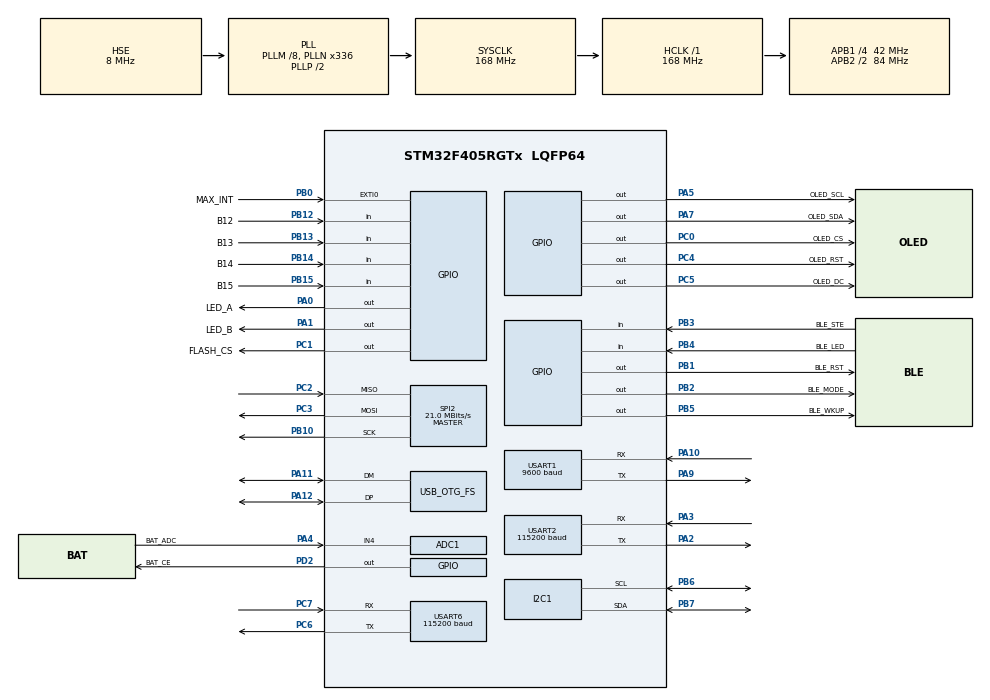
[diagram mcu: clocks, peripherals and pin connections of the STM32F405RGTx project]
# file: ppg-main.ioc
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ADC1.Channel-0\#ChannelRegularConversion=ADC_CHANNEL_4
ADC1.NbrOfConversionFlag=1
ADC1.Rank-0\#ChannelRegularConversion=1
ADC1.SamplingTime-0\#ChannelRegularConversion=ADC_SAMPLETIME_3CYCLES
ADC1.master=1
FATFS._MAX_SS=512
FATFS._MIN_SS=512
Mcu.Family=STM32F4
Mcu.Name=STM32F405RGTx
Mcu.Package=LQFP64
NVIC.OTG_FS_IRQn=true\:0\:0\:false\:false\:true\:false
NVIC.PriorityGroup=NVIC_PRIORITYGROUP_4
NVIC.TIM8_TRG_COM_TIM14_IRQn=true\:0\:0\:false\:false\:true\:false
NVIC.TimeBase=TIM8_TRG_COM_TIM14_IRQn
NVIC.TimeBaseIP=TIM14
PA0-WKUP.GPIO_Label=LED_A
PA0-WKUP.GPIO_Speed=GPIO_SPEED_FREQ_VERY_HIGH
PA0-WKUP.Signal=GPIO_Output
PA1.GPIO_Label=LED_B
PA1.GPIO_Speed=GPIO_SPEED_FREQ_VERY_HIGH
PA1.Signal=GPIO_Output
PA10.Mode=Asynchronous
PA10.Signal=USART1_RX
PA11.Mode=Device_Only
PA11.Signal=USB_OTG_FS_DM
PA12.Mode=Device_Only
PA12.Signal=USB_OTG_FS_DP
PA13.Mode=Serial_Wire
PA13.Signal=SYS_JTMS-SWDIO
PA14.Mode=Serial_Wire
PA14.Signal=SYS_JTCK-SWCLK
PA2.Mode=Asynchronous
PA2.Signal=USART2_TX
PA3.Mode=Asynchronous
PA3.Signal=USART2_RX
PA4.GPIO_Label=BAT_ADC
PA4.Signal=SharedAnalog_PA4
PA5.GPIO_Label=OLED_SCL
PA5.GPIO_Speed=GPIO_SPEED_FREQ_VERY_HIGH
PA5.Signal=GPIO_Output
PA7.GPIO_Label=OLED_SDA
PA7.GPIO_Speed=GPIO_SPEED_FREQ_VERY_HIGH
PA7.Signal=GPIO_Output
PA9.Mode=Asynchronous
PA9.Signal=USART1_TX
PB0.GPIO_Label=MAX_INT
PB0.Signal=GPXTI0
PB1.GPIO_Label=BLE_RST
PB1.GPIO_ModeDefaultOutputPP=GPIO_MODE_OUTPUT_OD
PB1.GPIO_PuPd=GPIO_NOPULL
PB1.GPIO_Speed=GPIO_SPEED_FREQ_VERY_HIGH
PB1.PinState=GPIO_PIN_SET
PB1.Signal=GPIO_Output
PB10.Mode=Full_Duplex_Master
PB10.Signal=SPI2_SCK
PB12.GPIO_Label=B12
PB12.GPIO_Mode=GPIO_MODE_INPUT
PB12.GPIO_PuPd=GPIO_PULLUP
PB12.Signal=GPIO_Input
PB13.GPIO_Label=B13
PB13.GPIO_Mode=GPIO_MODE_INPUT
PB13.GPIO_PuPd=GPIO_PULLUP
PB13.Signal=GPIO_Input
PB14.GPIO_Label=B14
PB14.GPIO_Mode=GPIO_MODE_INPUT
PB14.GPIO_PuPd=GPIO_PULLUP
PB14.Signal=GPIO_Input
PB15.GPIO_Label=B15
PB15.GPIO_Mode=GPIO_MODE_INPUT
PB15.GPIO_PuPd=GPIO_PULLUP
PB15.Signal=GPIO_Input
PB2.GPIO_Label=BLE_MODE
PB2.GPIO_ModeDefaultOutputPP=GPIO_MODE_OUTPUT_OD
PB2.GPIO_PuPd=GPIO_NOPULL
PB2.GPIO_Speed=GPIO_SPEED_FREQ_VERY_HIGH
PB2.PinState=GPIO_PIN_SET
PB2.Signal=GPIO_Output
PB3.GPIO_Label=BLE_STE
PB3.Signal=GPIO_Input
PB4.GPIO_Label=BLE_LED
PB4.Signal=GPIO_Input
PB5.GPIO_Label=BLE_WKUP
PB5.GPIO_ModeDefaultOutputPP=GPIO_MODE_OUTPUT_OD
PB5.GPIO_PuPd=GPIO_NOPULL
PB5.GPIO_Speed=GPIO_SPEED_FREQ_VERY_HIGH
PB5.PinState=GPIO_PIN_SET
PB5.Signal=GPIO_Output
PB6.Mode=I2C
PB6.Signal=I2C1_SCL
PB7.Mode=I2C
PB7.Signal=I2C1_SDA
PC0.GPIO_Label=OLED_CS
PC0.GPIO_Speed=GPIO_SPEED_FREQ_VERY_HIGH
PC0.PinState=GPIO_PIN_SET
PC0.Signal=GPIO_Output
PC1.GPIO_Label=FLASH_CS
PC1.GPIO_Speed=GPIO_SPEED_FREQ_VERY_HIGH
PC1.PinState=GPIO_PIN_SET
PC1.Signal=GPIO_Output
PC14-OSC32_IN.Mode=LSE-External-Oscillator
PC14-OSC32_IN.Signal=RCC_OSC32_IN
PC15-OSC32_OUT.Mode=LSE-External-Oscillator
PC15-OSC32_OUT.Signal=RCC_OSC32_OUT
PC2.Mode=Full_Duplex_Master
PC2.Signal=SPI2_MISO
PC3.Mode=Full_Duplex_Master
PC3.Signal=SPI2_MOSI
PC4.GPIO_Label=OLED_RST
PC4.GPIO_Speed=GPIO_SPEED_FREQ_VERY_HIGH
PC4.Signal=GPIO_Output
PC5.GPIO_Label=OLED_DC
PC5.GPIO_Speed=GPIO_SPEED_FREQ_VERY_HIGH
PC5.Signal=GPIO_Output
PC6.Mode=Asynchronous
PC6.Signal=USART6_TX
PC7.Mode=Asynchronous
PC7.Signal=USART6_RX
PD2.GPIO_Label=BAT_CE
PD2.GPIO_Speed=GPIO_SPEED_FREQ_VERY_HIGH
PD2.PinState=GPIO_PIN_SET
PD2.Signal=GPIO_Output
PH0-OSC_IN.Mode=HSE-External-Oscillator
PH0-OSC_IN.Signal=RCC_OSC_IN
PH1-OSC_OUT.Mode=HSE-External-Oscillator
PH1-OSC_OUT.Signal=RCC_OSC_OUT
ProjectManager.HeapSize=0x400
ProjectManager.StackSize=0x800
ProjectManager.TargetToolchain=SW4STM32
RCC.48MHZClocksFreq_Value=48000000
RCC.AHBFreq_Value=168000000
RCC.APB1CLKDivider=RCC_HCLK_DIV4
RCC.APB1Freq_Value=42000000
RCC.APB1TimFreq_Value=84000000
RCC.APB2CLKDivider=RCC_HCLK_DIV2
RCC.APB2Freq_Value=84000000
RCC.APB2TimFreq_Value=168000000
RCC.CortexFreq_Value=168000000
RCC.EnbaleCSS=true
RCC.HCLKFreq_Value=168000000
RCC.HSE_VALUE=8000000
RCC.HSICalibrationValue=8
RCC.HSI_VALUE=16000000
RCC.PLLM=8
RCC.PLLN=336
RCC.PLLQ=7
RCC.SYSCLKFreq_VALUE=168000000
RCC.SYSCLKSource=RCC_SYSCLKSOURCE_PLLCLK
RCC.VCOOutputFreq_Value=336000000
SH.SharedAnalog_PA4.0=GPIO_Analog
SH.SharedAnalog_PA4.1=ADC1_IN4,IN4
SPI2.BaudRatePrescaler=SPI_BAUDRATEPRESCALER_2
SPI2.CalculateBaudRate=21.0 MBits/s
SPI2.Direction=SPI_DIRECTION_2LINES
SPI2.Mode=SPI_MODE_MASTER
SPI2.VirtualType=VM_MASTER
USART1.BaudRate=9600
USART1.VirtualMode=VM_ASYNC
USART2.BaudRate=115200
USART2.VirtualMode=VM_ASYNC
USART6.BaudRate=115200
USART6.VirtualMode=VM_ASYNC
USB_DEVICE.CLASS_NAME_FS=MSC
USB_DEVICE.CONFIGURATION_STRING_MSC_FS=PPGColle Config
USB_DEVICE.INTERFACE_STRING_MSC_FS=PPGColle Interface
USB_DEVICE.MANUFACTURER_STRING-MSC_FS=NSDN
USB_DEVICE.PRODUCT_STRING_MSC_FS=PPGColle Storage
USB_DEVICE.VirtualMode-MSC_FS=Msc
USB_DEVICE.VirtualModeFS=Msc_FS
USB_OTG_FS.VirtualMode=Device_Only
VP_FATFS_VS_Generic.Mode=User_defined
VP_RNG_VS_RNG.Mode=RNG_Activate
VP_RTC_VS_RTC_Activate.Mode=RTC_Enabled
VP_SYS_VS_tim14.Mode=TIM14
VP_USB_DEVICE_VS_USB_DEVICE_MSC_FS.Mode=MSC_FS
board=ppg-main

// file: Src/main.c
/**
  ******************************************************************************
  * @file           : main.c
  * @brief          : Main program body
  ******************************************************************************
  * This notice applies to any and all portions of this file
  * that are not between comment pairs USER CODE BEGIN and
  * USER CODE END. Other portions of this file, whether
  * inserted by the user or by software development tools
  * are owned by their respective copyright owners.
  *
  * Copyright (c) 2018 STMicroelectronics International N.V.
  * All rights reserved.
  *
  * Redistribution and use in source and binary forms, with or without
  * modification, are permitted, provided that the following conditions are met:
  *
  * 1. Redistribution of source code must retain the above copyright notice,
  *    this list of conditions and the following disclaimer.
  * 2. Redistributions in binary form must reproduce the above copyright notice,
  *    this list of conditions and the following disclaimer in the documentation
  *    and/or other materials provided with the distribution.
  * 3. Neither the name of STMicroelectronics nor the names of other
  *    contributors to this software may be used to endorse or promote products
  *    derived from this software without specific written permission.
  * 4. This software, including modifications and/or derivative works of this
  *    software, must execute solely and exclusively on microcontroller or
  *    microprocessor devices manufactured by or for STMicroelectronics.
  * 5. Redistribution and use of this software other than as permitted under
  *    this license is void and will automatically terminate your rights under
  *    this license.
  *
  * THIS SOFTWARE IS PROVIDED BY STMICROELECTRONICS AND CONTRIBUTORS "AS IS"
  * AND ANY EXPRESS, IMPLIED OR STATUTORY WARRANTIES, INCLUDING, BUT NOT
  * LIMITED TO, THE IMPLIED WARRANTIES OF MERCHANTABILITY, FITNESS FOR A
  * PARTICULAR PURPOSE AND NON-INFRINGEMENT OF THIRD PARTY INTELLECTUAL PROPERTY
  * RIGHTS ARE DISCLAIMED TO THE FULLEST EXTENT PERMITTED BY LAW. IN NO EVENT
  * SHALL STMICROELECTRONICS OR CONTRIBUTORS BE LIABLE FOR ANY DIRECT, INDIRECT,
  * INCIDENTAL, SPECIAL, EXEMPLARY, OR CONSEQUENTIAL DAMAGES (INCLUDING, BUT NOT
  * LIMITED TO, PROCUREMENT OF SUBSTITUTE GOODS OR SERVICES; LOSS OF USE, DATA,
  * OR PROFITS; OR BUSINESS INTERRUPTION) HOWEVER CAUSED AND ON ANY THEORY OF
  * LIABILITY, WHETHER IN CONTRACT, STRICT LIABILITY, OR TORT (INCLUDING
  * NEGLIGENCE OR OTHERWISE) ARISING IN ANY WAY OUT OF THE USE OF THIS SOFTWARE,
  * EVEN IF ADVISED OF THE POSSIBILITY OF SUCH DAMAGE.
  *
  ******************************************************************************
  */
#include "main.h"
#include "stm32f4xx_hal.h"
#include "fatfs.h"
#include "usb_device.h"

/* USER CODE BEGIN Includes */
#include "ppg_bios.h"
#include "ppg_system.h"

/* USER CODE END Includes */

ADC_HandleTypeDef hadc1;

I2C_HandleTypeDef hi2c1;

RNG_HandleTypeDef hrng;

RTC_HandleTypeDef hrtc;

SPI_HandleTypeDef hspi2;

UART_HandleTypeDef huart1;
UART_HandleTypeDef huart2;
UART_HandleTypeDef huart6;

/* USER CODE BEGIN PV */
/* Private variables ---------------------------------------------------------*/
/* USER CODE END PV */

void SystemClock_Config(void);
static void MX_GPIO_Init(void);
static void MX_SPI2_Init(void);
static void MX_I2C1_Init(void);
static void MX_USART1_UART_Init(void);
static void MX_USART2_UART_Init(void);
static void MX_USART6_UART_Init(void);
static void MX_ADC1_Init(void);
static void MX_RNG_Init(void);
static void MX_RTC_Init(void);

/* USER CODE BEGIN PFP */
/* Private function prototypes -----------------------------------------------*/
/* USER CODE END PFP */

int main(void)
{

  /* MCU Configuration----------------------------------------------------------*/

  /* Reset of all peripherals, Initializes the Flash interface and the Systick. */
  HAL_Init();

  /* Configure the system clock */
  SystemClock_Config();

  /* Initialize all configured peripherals */
  MX_GPIO_Init();
  MX_SPI2_Init();
  MX_I2C1_Init();
  MX_USART1_UART_Init();
  MX_USART2_UART_Init();
  MX_USART6_UART_Init();
  MX_FATFS_Init();
  MX_USB_DEVICE_Init();
  MX_ADC1_Init();
  MX_RNG_Init();
  MX_RTC_Init();
  /* USER CODE BEGIN 2 */
  hardwareInit();

  /* USER CODE END 2 */

  /* Infinite loop */
  /* USER CODE BEGIN WHILE */
  while (1)
  {
	  systemWork();
  /* USER CODE END WHILE */

  }

}

void SystemClock_Config(void)
{

  RCC_OscInitTypeDef RCC_OscInitStruct;
  RCC_ClkInitTypeDef RCC_ClkInitStruct;
  RCC_PeriphCLKInitTypeDef PeriphClkInitStruct;

    /**Configure the main internal regulator output voltage
    */
  __HAL_RCC_PWR_CLK_ENABLE();

  __HAL_PWR_VOLTAGESCALING_CONFIG(PWR_REGULATOR_VOLTAGE_SCALE1);

    /**Initializes the CPU, AHB and APB busses clocks
    */
  RCC_OscInitStruct.OscillatorType = RCC_OSCILLATORTYPE_LSI|RCC_OSCILLATORTYPE_HSE;
  RCC_OscInitStruct.HSEState = RCC_HSE_ON;
  RCC_OscInitStruct.LSIState = RCC_LSI_ON;
  RCC_OscInitStruct.PLL.PLLState = RCC_PLL_ON;
  RCC_OscInitStruct.PLL.PLLSource = RCC_PLLSOURCE_HSE;
  RCC_OscInitStruct.PLL.PLLM = 8;
  RCC_OscInitStruct.PLL.PLLN = 336;
  RCC_OscInitStruct.PLL.PLLP = RCC_PLLP_DIV2;
  RCC_OscInitStruct.PLL.PLLQ = 7;
  if (HAL_RCC_OscConfig(&RCC_OscInitStruct) != HAL_OK)
  {
    _Error_Handler(__FILE__, __LINE__);
  }

    /**Initializes the CPU, AHB and APB busses clocks
    */
  RCC_ClkInitStruct.ClockType = RCC_CLOCKTYPE_HCLK|RCC_CLOCKTYPE_SYSCLK
                              |RCC_CLOCKTYPE_PCLK1|RCC_CLOCKTYPE_PCLK2;
  RCC_ClkInitStruct.SYSCLKSource = RCC_SYSCLKSOURCE_PLLCLK;
  RCC_ClkInitStruct.AHBCLKDivider = RCC_SYSCLK_DIV1;
  RCC_ClkInitStruct.APB1CLKDivider = RCC_HCLK_DIV4;
  RCC_ClkInitStruct.APB2CLKDivider = RCC_HCLK_DIV2;

  if (HAL_RCC_ClockConfig(&RCC_ClkInitStruct, FLASH_LATENCY_5) != HAL_OK)
  {
    _Error_Handler(__FILE__, __LINE__);
  }

  PeriphClkInitStruct.PeriphClockSelection = RCC_PERIPHCLK_RTC;
  PeriphClkInitStruct.RTCClockSelection = RCC_RTCCLKSOURCE_LSI;
  if (HAL_RCCEx_PeriphCLKConfig(&PeriphClkInitStruct) != HAL_OK)
  {
    _Error_Handler(__FILE__, __LINE__);
  }

    /**Enables the Clock Security System
    */
  HAL_RCC_EnableCSS();

    /**Configure the Systick interrupt time
    */
  HAL_SYSTICK_Config(HAL_RCC_GetHCLKFreq()/1000);

    /**Configure the Systick
    */
  HAL_SYSTICK_CLKSourceConfig(SYSTICK_CLKSOURCE_HCLK);

  /* SysTick_IRQn interrupt configuration */
  HAL_NVIC_SetPriority(SysTick_IRQn, 0, 0);
}

/* ADC1 init function */
static void MX_ADC1_Init(void)
{

  ADC_ChannelConfTypeDef sConfig;

    /**Configure the global features of the ADC (Clock, Resolution, Data Alignment and number of conversion)
    */
  hadc1.Instance = ADC1;
  hadc1.Init.ClockPrescaler = ADC_CLOCK_SYNC_PCLK_DIV4;
  hadc1.Init.Resolution = ADC_RESOLUTION_12B;
  hadc1.Init.ScanConvMode = DISABLE;
  hadc1.Init.ContinuousConvMode = DISABLE;
  hadc1.Init.DiscontinuousConvMode = DISABLE;
  hadc1.Init.ExternalTrigConvEdge = ADC_EXTERNALTRIGCONVEDGE_NONE;
  hadc1.Init.ExternalTrigConv = ADC_SOFTWARE_START;
  hadc1.Init.DataAlign = ADC_DATAALIGN_RIGHT;
  hadc1.Init.NbrOfConversion = 1;
  hadc1.Init.DMAContinuousRequests = DISABLE;
  hadc1.Init.EOCSelection = ADC_EOC_SINGLE_CONV;
  if (HAL_ADC_Init(&hadc1) != HAL_OK)
  {
    _Error_Handler(__FILE__, __LINE__);
  }

    /**Configure for the selected ADC regular channel its corresponding rank in the sequencer and its sample time.
    */
  sConfig.Channel = ADC_CHANNEL_4;
  sConfig.Rank = 1;
  sConfig.SamplingTime = ADC_SAMPLETIME_3CYCLES;
  if (HAL_ADC_ConfigChannel(&hadc1, &sConfig) != HAL_OK)
  {
    _Error_Handler(__FILE__, __LINE__);
  }

}

/* I2C1 init function */
static void MX_I2C1_Init(void)
{

  hi2c1.Instance = I2C1;
  hi2c1.Init.ClockSpeed = 100000;
  hi2c1.Init.DutyCycle = I2C_DUTYCYCLE_2;
  hi2c1.Init.OwnAddress1 = 0;
  hi2c1.Init.AddressingMode = I2C_ADDRESSINGMODE_7BIT;
  hi2c1.Init.DualAddressMode = I2C_DUALADDRESS_DISABLE;
  hi2c1.Init.OwnAddress2 = 0;
  hi2c1.Init.GeneralCallMode = I2C_GENERALCALL_DISABLE;
  hi2c1.Init.NoStretchMode = I2C_NOSTRETCH_DISABLE;
  if (HAL_I2C_Init(&hi2c1) != HAL_OK)
  {
    _Error_Handler(__FILE__, __LINE__);
  }

}

/* RNG init function */
static void MX_RNG_Init(void)
{

  hrng.Instance = RNG;
  if (HAL_RNG_Init(&hrng) != HAL_OK)
  {
    _Error_Handler(__FILE__, __LINE__);
  }

}

/* RTC init function */
static void MX_RTC_Init(void)
{

    /**Initialize RTC Only
    */
  hrtc.Instance = RTC;
  hrtc.Init.HourFormat = RTC_HOURFORMAT_24;
  hrtc.Init.AsynchPrediv = 127;
  hrtc.Init.SynchPrediv = 255;
  hrtc.Init.OutPut = RTC_OUTPUT_DISABLE;
  hrtc.Init.OutPutPolarity = RTC_OUTPUT_POLARITY_HIGH;
  hrtc.Init.OutPutType = RTC_OUTPUT_TYPE_OPENDRAIN;
  if (HAL_RTC_Init(&hrtc) != HAL_OK)
  {
    _Error_Handler(__FILE__, __LINE__);
  }

}

/* SPI2 init function */
static void MX_SPI2_Init(void)
{

  /* SPI2 parameter configuration*/
  hspi2.Instance = SPI2;
  hspi2.Init.Mode = SPI_MODE_MASTER;
  hspi2.Init.Direction = SPI_DIRECTION_2LINES;
  hspi2.Init.DataSize = SPI_DATASIZE_8BIT;
  hspi2.Init.CLKPolarity = SPI_POLARITY_LOW;
  hspi2.Init.CLKPhase = SPI_PHASE_1EDGE;
  hspi2.Init.NSS = SPI_NSS_SOFT;
  hspi2.Init.BaudRatePrescaler = SPI_BAUDRATEPRESCALER_2;
  hspi2.Init.FirstBit = SPI_FIRSTBIT_MSB;
  hspi2.Init.TIMode = SPI_TIMODE_DISABLE;
  hspi2.Init.CRCCalculation = SPI_CRCCALCULATION_DISABLE;
  hspi2.Init.CRCPolynomial = 10;
  if (HAL_SPI_Init(&hspi2) != HAL_OK)
  {
    _Error_Handler(__FILE__, __LINE__);
  }

}

/* USART1 init function */
static void MX_USART1_UART_Init(void)
{

  huart1.Instance = USART1;
  huart1.Init.BaudRate = 9600;
  huart1.Init.WordLength = UART_WORDLENGTH_8B;
  huart1.Init.StopBits = UART_STOPBITS_1;
  huart1.Init.Parity = UART_PARITY_NONE;
  huart1.Init.Mode = UART_MODE_TX_RX;
  huart1.Init.HwFlowCtl = UART_HWCONTROL_NONE;
  huart1.Init.OverSampling = UART_OVERSAMPLING_16;
  if (HAL_UART_Init(&huart1) != HAL_OK)
  {
    _Error_Handler(__FILE__, __LINE__);
  }

}

/* USART2 init function */
static void MX_USART2_UART_Init(void)
{

  huart2.Instance = USART2;
  huart2.Init.BaudRate = 115200;
  huart2.Init.WordLength = UART_WORDLENGTH_8B;
  huart2.Init.StopBits = UART_STOPBITS_1;
  huart2.Init.Parity = UART_PARITY_NONE;
  huart2.Init.Mode = UART_MODE_TX_RX;
  huart2.Init.HwFlowCtl = UART_HWCONTROL_NONE;
  huart2.Init.OverSampling = UART_OVERSAMPLING_16;
  if (HAL_UART_Init(&huart2) != HAL_OK)
  {
    _Error_Handler(__FILE__, __LINE__);
  }

}

/* USART6 init function */
static void MX_USART6_UART_Init(void)
{

  huart6.Instance = USART6;
  huart6.Init.BaudRate = 115200;
  huart6.Init.WordLength = UART_WORDLENGTH_8B;
  huart6.Init.StopBits = UART_STOPBITS_1;
  huart6.Init.Parity = UART_PARITY_NONE;
  huart6.Init.Mode = UART_MODE_TX_RX;
  huart6.Init.HwFlowCtl = UART_HWCONTROL_NONE;
  huart6.Init.OverSampling = UART_OVERSAMPLING_16;
  if (HAL_UART_Init(&huart6) != HAL_OK)
  {
    _Error_Handler(__FILE__, __LINE__);
  }

}

/** Configure pins as
        * Analog
        * Input
        * Output
        * EVENT_OUT
        * EXTI
     PA4   ------> SharedAnalog_PA4
*/
static void MX_GPIO_Init(void)
{

  GPIO_InitTypeDef GPIO_InitStruct;

  /* GPIO Ports Clock Enable */
  __HAL_RCC_GPIOC_CLK_ENABLE();
  __HAL_RCC_GPIOH_CLK_ENABLE();
  __HAL_RCC_GPIOA_CLK_ENABLE();
  __HAL_RCC_GPIOB_CLK_ENABLE();
  __HAL_RCC_GPIOD_CLK_ENABLE();

  /*Configure GPIO pin Output Level */
  HAL_GPIO_WritePin(GPIOC, OLED_CS_Pin|FLASH_CS_Pin, GPIO_PIN_SET);

  /*Configure GPIO pin Output Level */
  HAL_GPIO_WritePin(GPIOA, LED_A_Pin|LED_B_Pin|OLED_SCL_Pin|OLED_SDA_Pin, GPIO_PIN_RESET);

  /*Configure GPIO pin Output Level */
  HAL_GPIO_WritePin(GPIOC, OLED_RST_Pin|OLED_DC_Pin, GPIO_PIN_RESET);

  /*Configure GPIO pin Output Level */
  HAL_GPIO_WritePin(GPIOB, BLE_RST_Pin|BLE_MODE_Pin|BLE_WKUP_Pin, GPIO_PIN_SET);

  /*Configure GPIO pin Output Level */
  HAL_GPIO_WritePin(BAT_CE_GPIO_Port, BAT_CE_Pin, GPIO_PIN_SET);

  /*Configure GPIO pins : OLED_CS_Pin FLASH_CS_Pin OLED_RST_Pin OLED_DC_Pin */
  GPIO_InitStruct.Pin = OLED_CS_Pin|FLASH_CS_Pin|OLED_RST_Pin|OLED_DC_Pin;
  GPIO_InitStruct.Mode = GPIO_MODE_OUTPUT_PP;
  GPIO_InitStruct.Pull = GPIO_NOPULL;
  GPIO_InitStruct.Speed = GPIO_SPEED_FREQ_VERY_HIGH;
  HAL_GPIO_Init(GPIOC, &GPIO_InitStruct);

  /*Configure GPIO pins : LED_A_Pin LED_B_Pin OLED_SCL_Pin OLED_SDA_Pin */
  GPIO_InitStruct.Pin = LED_A_Pin|LED_B_Pin|OLED_SCL_Pin|OLED_SDA_Pin;
  GPIO_InitStruct.Mode = GPIO_MODE_OUTPUT_PP;
  GPIO_InitStruct.Pull = GPIO_NOPULL;
  GPIO_InitStruct.Speed = GPIO_SPEED_FREQ_VERY_HIGH;
  HAL_GPIO_Init(GPIOA, &GPIO_InitStruct);

  /*Configure GPIO pin : BAT_ADC_Pin */
  GPIO_InitStruct.Pin = BAT_ADC_Pin;
  GPIO_InitStruct.Mode = GPIO_MODE_ANALOG;
  GPIO_InitStruct.Pull = GPIO_NOPULL;
  HAL_GPIO_Init(BAT_ADC_GPIO_Port, &GPIO_InitStruct);

  /*Configure GPIO pin : MAX_INT_Pin */
  GPIO_InitStruct.Pin = MAX_INT_Pin;
  GPIO_InitStruct.Mode = GPIO_MODE_IT_RISING;
  GPIO_InitStruct.Pull = GPIO_NOPULL;
  HAL_GPIO_Init(MAX_INT_GPIO_Port, &GPIO_InitStruct);

  /*Configure GPIO pins : BLE_RST_Pin BLE_MODE_Pin BLE_WKUP_Pin */
  GPIO_InitStruct.Pin = BLE_RST_Pin|BLE_MODE_Pin|BLE_WKUP_Pin;
  GPIO_InitStruct.Mode = GPIO_MODE_OUTPUT_OD;
  GPIO_InitStruct.Pull = GPIO_NOPULL;
  GPIO_InitStruct.Speed = GPIO_SPEED_FREQ_VERY_HIGH;
  HAL_GPIO_Init(GPIOB, &GPIO_InitStruct);

  /*Configure GPIO pins : B12_Pin B13_Pin B14_Pin B15_Pin */
  GPIO_InitStruct.Pin = B12_Pin|B13_Pin|B14_Pin|B15_Pin;
  GPIO_InitStruct.Mode = GPIO_MODE_INPUT;
  GPIO_InitStruct.Pull = GPIO_PULLUP;
  HAL_GPIO_Init(GPIOB, &GPIO_InitStruct);

  /*Configure GPIO pin : BAT_CE_Pin */
  GPIO_InitStruct.Pin = BAT_CE_Pin;
  GPIO_InitStruct.Mode = GPIO_MODE_OUTPUT_PP;
  GPIO_InitStruct.Pull = GPIO_NOPULL;
  GPIO_InitStruct.Speed = GPIO_SPEED_FREQ_VERY_HIGH;
  HAL_GPIO_Init(BAT_CE_GPIO_Port, &GPIO_InitStruct);

  /*Configure GPIO pins : BLE_STE_Pin BLE_LED_Pin */
  GPIO_InitStruct.Pin = BLE_STE_Pin|BLE_LED_Pin;
  GPIO_InitStruct.Mode = GPIO_MODE_INPUT;
  GPIO_InitStruct.Pull = GPIO_NOPULL;
  HAL_GPIO_Init(GPIOB, &GPIO_InitStruct);

}

void HAL_TIM_PeriodElapsedCallback(TIM_HandleTypeDef *htim)
{
  if (htim->Instance == TIM14) {
    HAL_IncTick();
  }
}

void _Error_Handler(char *file, int line)
{
  while(1)
  {
  }
}

/************************ (C) COPYRIGHT STMicroelectronics *****END OF FILE****/
